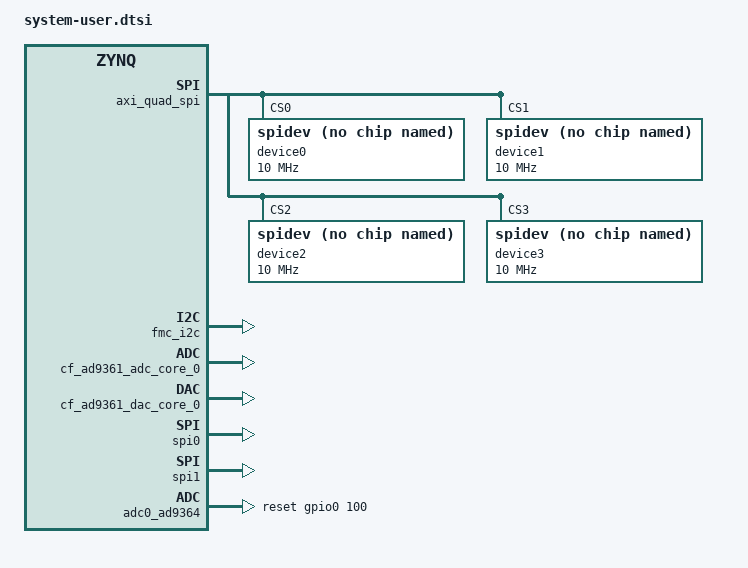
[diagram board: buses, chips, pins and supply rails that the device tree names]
/include/ "system-conf.dtsi"
/{
};

/include/ "zynq-zed-adv7511.dtsi"
&amba_pl {
	
	/delete-node/ axi_ad9361@79020000;
	/delete-node/ axi_dmac@7c400000;
	/delete-node/ axi_dmac@7c420000;
	/delete-node/ axi_clkgen@79000000;
	/delete-node/ axi_hdmi_tx@70e00000; 
	/delete-node/ dma@43000000;
	/delete-node/ axi_i2s_adi@77600000;
	/delete-node/ axi_spdif_tx@75c00000;
	
	axi_quad_spi: axi_quad_spi@43c00000 {
		#address-cells = <2>;
		#size-cells = <1>;
		bits-per-word = <8>;
		compatible = "xlnx,xps-spi-2.00.a";
		fifo-size = <16>;
		interrupt-parent = <&intc>;
		interrupts = <0 54 1>; /* auto-generated <0 34 1>; */
		num-cs = <0x4>;
		reg = <0x43c00000 0x10000>;
		xlnx,num-ss-bits = <0x4>;
		xlnx,spi-mode = <0>;
		#bus-num=<0>;
		status = "okay";
		device0: device0@0 {
			#address-cells = <1>;
			#size-cells = <0>;
 			reg = <0>;
			compatible = "linux,spidev";
		        spi-max-frequency = <10000000>;
			
		};
		device1: device1@1 {
			#address-cells = <1>;
			#size-cells = <0>;
 			reg = <1>;
			compatible = "linux,spidev";
		        spi-max-frequency = <10000000>;
			
		};
		device2: device2@2 {
			#address-cells = <1>;
			#size-cells = <0>;
 			reg = <2>;
			compatible = "linux,spidev";
		        spi-max-frequency = <10000000>;
			
		};
		device3: device3@3 {
			#address-cells = <1>;
			#size-cells = <0>;
 			reg = <3>;
			compatible = "linux,spidev";
		        spi-max-frequency = <10000000>;
			
		};
		
	};
	fmc_i2c: i2c@41620000 {
		compatible = "xlnx,axi-iic-1.01.b", "xlnx,xps-iic-2.00.a";
		reg = <0x41620000 0x10000>;
		interrupt-parent = <&intc>;
		interrupts = <0 55 0x4>;
		clocks = <&clkc 15>;
		clock-names = "pclk";

		#size-cells = <0>;
		#address-cells = <1>;
	};

	rx_dma: dma@7c400000 {
		compatible = "adi,axi-dmac-1.00.a";
		reg = <0x7c400000 0x10000>;
		interrupt-parent = <&intc>;
		#dma-cells = <1>;
		interrupts = <0 57 0>;
		clocks = <&clkc 16>;

		adi,channels {
			#size-cells = <0>;
			#address-cells = <1>;

			dma-channel@0 {
				reg = <0>;
				adi,source-bus-width = <64>;
				adi,source-bus-type = <2>;
				adi,destination-bus-width = <64>;
				adi,destination-bus-type = <0>;
				adi,length-width = <24>;
			};
		};
	};

	tx_dma: dma@7c420000 {
		compatible = "adi,axi-dmac-1.00.a";
		reg = <0x7c420000 0x10000>;
		interrupt-parent = <&intc>;
		#dma-cells = <1>;
		interrupts = <0 56 0>;
		clocks = <&clkc 16>;

		adi,channels {
			#size-cells = <0>;
			#address-cells = <1>;

			dma-channel@0 {
				reg = <0>;
				adi,source-bus-width = <64>;
				adi,source-bus-type = <0>;
				adi,destination-bus-width = <64>;
				adi,destination-bus-type = <2>;
				adi,length-width = <24>;
				adi,cyclic;
			};
		};
	};

	cf_ad9361_adc_core_0: cf-ad9361-lpc@79020000 {
		compatible = "adi,axi-ad9361-6.00.a";
		reg = <0x79020000 0x6000>;
		dmas = <&rx_dma 0>;
		dma-names = "rx";

		spibus-connected = <&adc0_ad9364>;
	};

	cf_ad9361_dac_core_0: cf-ad9361-dds-core-lpc@79024000 {
		compatible = "adi,axi-ad9364-dds-6.00.a";
		reg = <0x79024000 0x1000>;
		clocks = <&adc0_ad9364 13>;
		clock-names = "sampl_clk";
		adi,axi-dds-rate = <1>; /* use 1 for 1RX1TX mode */
		adi,axi-dds-1-rf-channel;
		dmas = <&tx_dma 0>;
		dma-names = "tx";
	};
	
	
};

	
	 

&spi0 {
	status = "okay";
};

&spi1 {
	status = "okay";
};

#define fmc_spi spi0
#define pmod_spi spi1

#include "adi-fmcomms4.dtsi"
#include "adi-fmcomms3-up-down-converter.dtsi"

&adc0_ad9364 {
	en_agc-gpios  = <&gpio0 98 0>;
	sync-gpios  = <&gpio0 99 0>;
	reset-gpios = <&gpio0 100 0>;
	enable-gpios = <&gpio0 101 0>;
	txnrx-gpios = <&gpio0 102 0>;
};

&lo_pll0_rx_adf4351 {
	gpios = <&gpio0 103 0>;
};

&lo_pll0_tx_adf4351 {
	gpios = <&gpio0 104 0>;
};

/{
};
